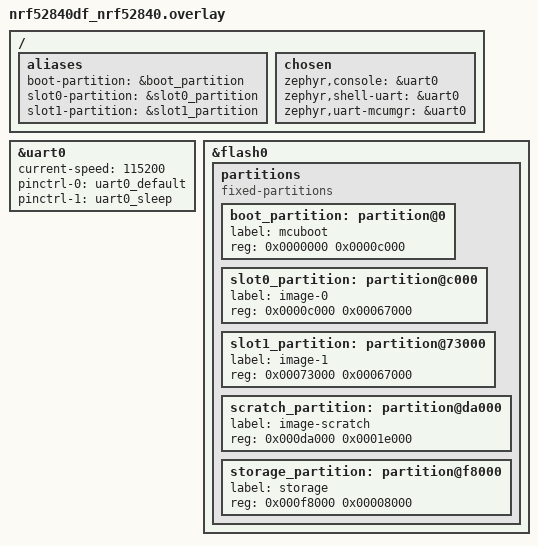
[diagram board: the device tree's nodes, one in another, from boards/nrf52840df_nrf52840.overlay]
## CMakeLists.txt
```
cmake_minimum_required(VERSION 3.20.0)
find_package(Zephyr REQUIRED HINTS $ENV{ZEPHYR_BASE})

project(MCUboot)

target_sources(app PRIVATE src/main.c)
```

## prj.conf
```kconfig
CONFIG_BOOTLOADER_MCUBOOT=y

# Application logging
CONFIG_LOG=y
CONFIG_PRINTK=y
CONFIG_CONSOLE=y
CONFIG_UART_CONSOLE=y
CONFIG_SERIAL=y
CONFIG_USE_SEGGER_RTT=y
CONFIG_RTT_CONSOLE=y
```

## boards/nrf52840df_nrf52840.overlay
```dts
/ {
    aliases {
        boot-partition = &boot_partition;
        slot0-partition = &slot0_partition;
        slot1-partition = &slot1_partition;
    };

    chosen {
        zephyr,console = &uart0;
        zephyr,shell-uart = &uart0;
        zephyr,uart-mcumgr = &uart0;
    };
};

&uart0 {
    status = "okay";
    current-speed = <115200>;
    pinctrl-0 = <&uart0_default>;
    pinctrl-1 = <&uart0_sleep>;
    pinctrl-names = "default", "sleep";
};

&flash0 {
    partitions {
        compatible = "fixed-partitions";
        #address-cells = <1>;
        #size-cells = <1>;

        boot_partition: partition@0 {
            label = "mcuboot";
            reg = <0x0000000 0x0000c000>;
        };

        slot0_partition: partition@c000 {
            label = "image-0";
            reg = <0x0000c000 0x00067000>;
        };

        slot1_partition: partition@73000 {
            label = "image-1";
            reg = <0x00073000 0x00067000>;
        };

        scratch_partition: partition@da000 {
            label = "image-scratch";
            reg = <0x000da000 0x0001e000>;
        };

        storage_partition: partition@f8000 {
            label = "storage";
            reg = <0x000f8000 0x00008000>;
        };
    };
};
```

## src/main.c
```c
#include <zephyr/kernel.h>
#include <zephyr/logging/log.h>

LOG_MODULE_REGISTER(main, LOG_LEVEL_INF);

int main(void)
{
    printk("\n========================================\n");
    printk("=== MCUboot -> Application Transition ===\n");
    printk("*** Application started ***\n");
    printk("Current uptime: %lld ms\n", k_uptime_get());
    printk("MCUboot successfully handed over control to application\n");
    printk("If uptime is very small, MCUboot completed very quickly\n");
    printk("Expected: Should see 5+ second delay if MCUboot config worked\n");
    printk("========================================\n\n");
    
    LOG_INF("Application main() started at uptime: %lld ms", k_uptime_get());
    LOG_INF("MCUboot -> Application transition complete");
    
    while (1) {
        LOG_INF("Application running... uptime: %lld ms", k_uptime_get());
        k_sleep(K_SECONDS(5));
    }
    
    return 0;
}
```
